# BlueNRG_LPS register map
File version: 1.0
CPU: CM0+ r0p0, little endian, no MPU, no FPU, 2 interrupt priority bits
Registers are 32-bit, read-write, reset 0x0 unless marked. A register's access mark holds for its fields unless they carry their own. Offsets are from the block's base; [hi:lo] are bit positions; {n}, {i} and the like mark numbered series.

## SYSCFG — System configuration controller
Base 0x40000000
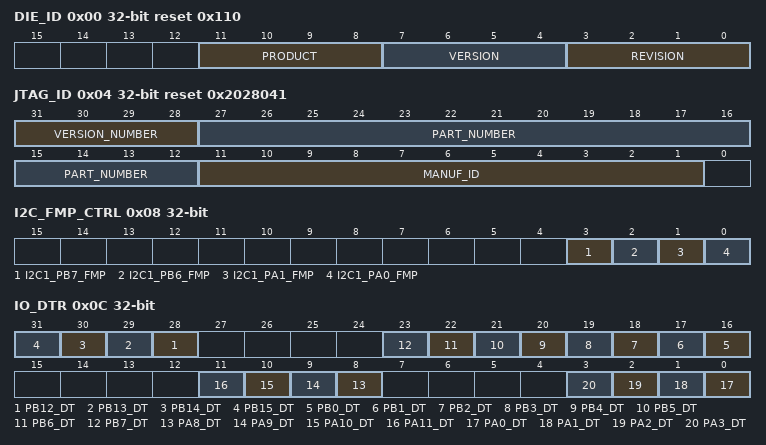
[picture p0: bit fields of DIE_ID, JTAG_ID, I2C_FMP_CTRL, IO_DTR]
0x00 DIE_ID ro reset 0x110 — This register provides the device version and cut information.
  [11:8] PRODUCT — Product version.
  [7:4] VERSION — Cut version.
  [3:0] REVISION — Cut revision (metal fix)
0x04 JTAG_ID ro reset 0x2028041 — This register provides the JTAG ID of the BlueNRG-LP.
  [31:28] VERSION_NUMBER — Version.
  [27:12] PART_NUMBER
  [11:1] MANUF_ID — Manufacturer ID.
0x08 I2C_FMP_CTRL — This register allows activating the Fast-mode Plus driving capability on I2C open-drain pads.
  [3] I2C1_PB7_FMP — I2C1 Fast-Mode Plus driving capability for I2C1_SDA on PB7 I/O.
  [2] I2C1_PB6_FMP — I2C1 Fast-Mode Plus driving capability for I2C1_SCL on PB6 I/O
  [1] I2C1_PA1_FMP — I2C1 Fast-Mode Plus driving capability for I2C1_SDA on PA1 I/O
  [0] I2C1_PA0_FMP — I2C1 Fast-Mode Plus driving capability for I2C1_SCL on PA0 I/O
0x0C IO_DTR
  [n+16] PB{n}_DT (n=12..15) — Interrupt Detection Type for port B
  [n+16] PB{n}_DT (n=0..7) — Interrupt Detection Type for port B
  [n] PA{n}_DT (n=8..11) — Interrupt Detection Type for port A
  [n] PA{n}_DT (n=0..3) — Interrupt Detection Type for port A
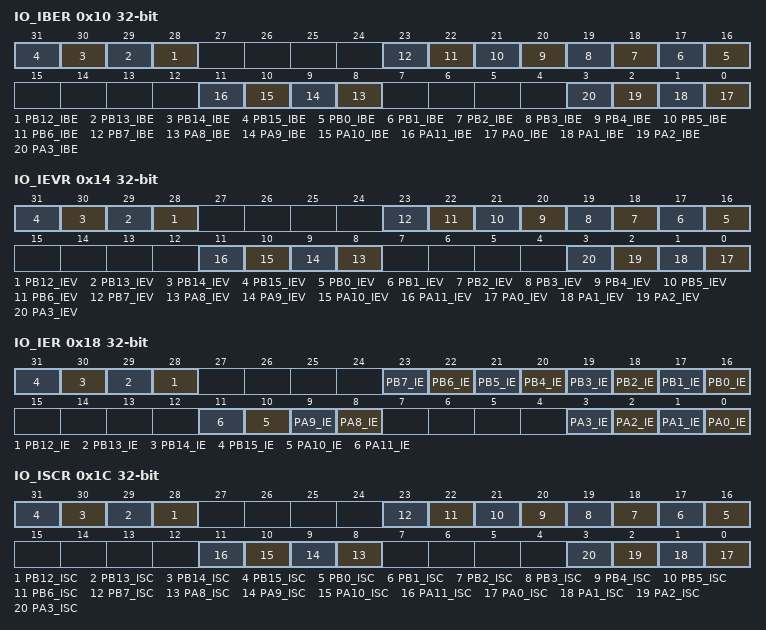
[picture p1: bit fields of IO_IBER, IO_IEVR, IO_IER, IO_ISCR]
0x10 IO_IBER
  [n+16] PB{n}_IBE (n=12..15) — Interrupt edge selection for port B
  [n+16] PB{n}_IBE (n=0..7) — Interrupt edge selection for port B
  [n] PA{n}_IBE (n=8..11) — Interrupt edge selection for port A
  [n] PA{n}_IBE (n=0..3) — Interrupt edge selection for port A
0x14 IO_IEVR — I/O Interrupt polarity event register
  [n+16] PB{n}_IEV (n=12..15) — Interrupt polarity event for port B
  [n+16] PB{n}_IEV (n=0..7) — Interrupt polarity event for port B
  [n] PA{n}_IEV (n=8..11) — Interrupt polarity event for port A
  [n] PA{n}_IEV (n=0..3) — Interrupt polarity event for port A
0x18 IO_IER — I/O Interrupt Enable register
  [n+16] PB{n}_IE (n=12..15) — Interrupt enable for port B
  [n+16] PB{n}_IE (n=0..7) — Interrupt enable for port B
  [n] PA{n}_IE (n=8..11) — Interrupt enable for port A
  [n] PA{n}_IE (n=0..3) — Interrupt enable for port A
0x1C IO_ISCR — I/O Interrupt Status and Clear register
  [n+16] PB{n}_ISC (n=12..15) — Interrupt status (before mask) for port B
  [n+16] PB{n}_ISC (n=0..7) — Interrupt status (before mask) for port B
  [n] PA{n}_ISC (n=8..11) — Interrupt status (before mask) for port A
  [n] PA{n}_ISC (n=0..3) — Interrupt status (before mask) for port A
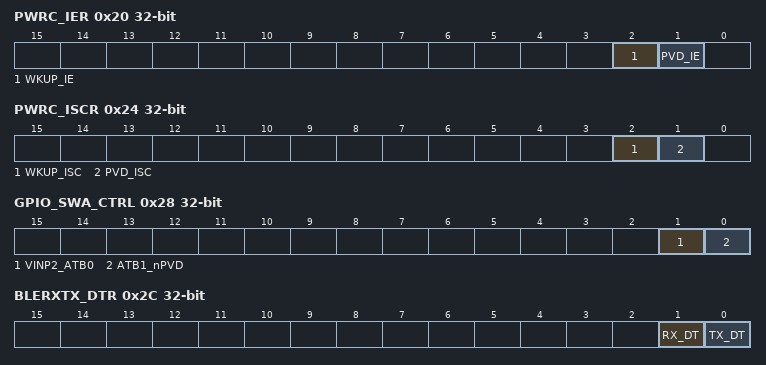
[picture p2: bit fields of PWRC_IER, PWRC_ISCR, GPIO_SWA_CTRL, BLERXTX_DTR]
0x20 PWRC_IER — This register allows control of the enable or mask on the interrupt sources of the Power Controller (PWRC) block.
  [2] WKUP_IE — Power Controller Wakeup event interrupt enable.
  [1] PVD_IE — Programmable Voltage Detector interrupt enable.
0x24 PWRC_ISCR — Power Controller Interrupt Status and Clear register
  [2] WKUP_ISC — Indicates the Power Controller receives a Wakeup event.
  [1] PVD_ISC — Programmable Voltage Detector status.
0x28 GPIO_SWA_CTRL — This register allows selecting the analog source to connect on analog pads embedding two features
  [1] VINP2_ATB0 — select the analog feature on PA3 between VINP2 and ATB0 when the PA3 I/O is programmed in analog mode, in the associated GPIO_MODER register
  [0] ATB1_nPVD — select the analog feature on PB14 between ATB1 and PVD when the PB14 IO is programmed in analog mode
0x2C BLERXTX_DTR — This register allows selecting the type of detection,level or edge, on RX_SEQUENCE and TX_SEQUENCE coming from the MR_BLE IP.
  [1] RX_DT — detection type on RX_SEQUENCE signal
  [0] TX_DT — detection type on TX_SEQUENCE signal
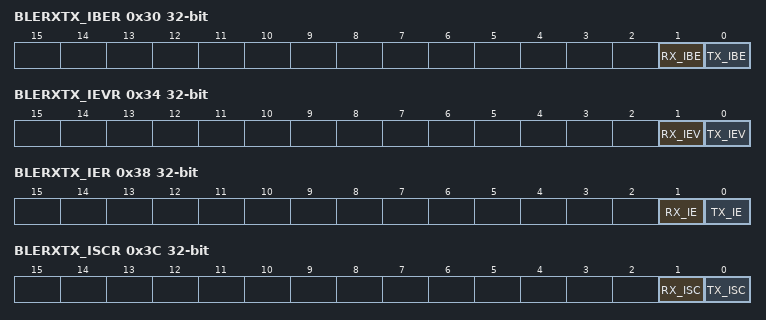
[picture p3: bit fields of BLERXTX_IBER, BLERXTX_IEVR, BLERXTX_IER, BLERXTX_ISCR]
0x30 BLERXTX_IBER — This register is used to activate RX_SEQUENCE and TX_SEQUENCE signal detection on single edge or both edges when edge detection type is active.
  [1] RX_IBE — interrupt edge register on RX_SEQUENCE signal
  [0] TX_IBE — interrupt edge register on TX_SEQUENCE signal
0x34 BLERXTX_IEVR — This register defines the polarity of the RX_SEQUENCE and TX_SEQUENCE signals detection
  [1] RX_IEV — interrupt polarity event on RX_SEQUENCE signal
  [0] TX_IEV — interrupt polarity event on TX_SEQUENCE signal
0x38 BLERXTX_IER — This register enable/disable interrupt generation on the RX_SEQUENCE and TX_SEQUENCE signals detection.
  [1] RX_IE — interrupt enable on RX_SEQUENCE signal
  [0] TX_IE — interrupt enable on TX_SEQUENCE signal
0x3C BLERXTX_ISCR — This register allows checking the status and clear the interrupt linked to the RX_SEQUENCE and TX_SEQUENCE information provided by the MR_BLE IP
  [1] RX_ISC — interrupt status on RX_SEQUENCE signal, can be a rising or a falling edge
  [0] TX_ISC — interrupt status on TX_SEQUENCE signal, can be a rising or a falling edge
